VERSION ""

NS_ :

BS_:

BU_: OffBoardDiagnosticTool1 Modine_40TC0063
VAL_TABLE_ FE 255 "Not Used" 254 "Unavailable" ;
VAL_TABLE_ FEFF 65535 "Not Used" 65279 "Unavailable" ;
VAL_TABLE_ exv_state_machine 3 "Complete" 2 "In Process" 1 "Start Request" 0 "Idle" ;
VAL_TABLE_ Manual_off_16 65535 "Manual mode disabled" ;
VAL_TABLE_ Manual_off_8 255 "Manual mode disabled" ;
VAL_TABLE_ cond_pressure_override 1 "On - set to 1450 kPa-g" 0 "Off - Auto pressure SP" ;
VAL_TABLE_ Pressure_switch 3 "Invalid" 1 "Closed (OK)" 0 "Open (fault)" ;
VAL_TABLE_ Digital_in 3 "Invalid" 1 "High (24V)" 0 "Low (0V)" ;

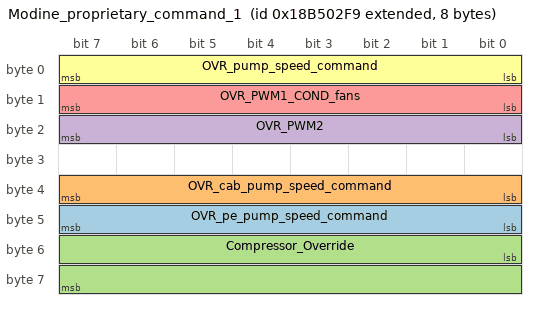
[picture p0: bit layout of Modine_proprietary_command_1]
BO_ 2561999609 Modine_proprietary_command_1: 8 OffBoardDiagnosticTool1
 SG_ OVR_pe_pump_speed_command : 40|8@1+ (0.5,0) [0|127.5] "%" Vector__XXX
 SG_ OVR_cab_pump_speed_command : 32|8@1+ (0.5,0) [0|127.5] "%" Vector__XXX
 SG_ Compressor_Override : 48|16@1+ (1,0) [0|65535] "" Vector__XXX
 SG_ OVR_PWM2 : 16|8@1+ (0.5,0) [0|127.5] "%"  Modine_40TC0063
 SG_ OVR_PWM1_COND_fans : 8|8@1+ (0.5,0) [0|127.5] "%"  Modine_40TC0063
 SG_ OVR_pump_speed_command : 0|8@1+ (0.5,0) [0|127.5] "%"  Modine_40TC0063

CM_ "V1.0 - Initial Release";
CM_ SG_ 2561999609 OVR_pe_pump_speed_command "Transmit 0xFF to disable";
CM_ SG_ 2561999609 OVR_cab_pump_speed_command "Transmit 0xFF to disable";
CM_ SG_ 2561999609 OVR_PWM1_COND_fans "3% - Fan off
20% - Fan reverse
40% - Minimum forward speed
90%+ - Maximum forward speed";
CM_ SG_ 2561999609 OVR_pump_speed_command "Transmit 0xFF to disable";
BA_DEF_ SG_  "J1939SLOT" STRING ;
BA_DEF_  "BaudRate" STRING ;
BA_DEF_  "DatabaseVersionDate" STRING ;
BA_DEF_  "DatabaseVersion" STRING ;
BA_DEF_ SG_  "SigType" ENUM  "Default","Range","RangeSigned","ASCII","Discrete","Control","ReferencePGN","DTC","StringDelimiter","StringLength","StringLengthControl","MessageCounter","MessageChecksum";
BA_DEF_ SG_  "GenSigEVName" STRING ;
BA_DEF_ SG_  "GenSigILSupport" ENUM  "No","Yes";
BA_DEF_ SG_  "GenSigSendType" ENUM  "Cyclic","OnWrite","OnWriteWithRepetition","OnChange","OnChangeWithRepetition","IfActive","IfActiveWithRepetition","NoSigSendType";
BA_DEF_ SG_  "GenSigStartValue" INT 0 2147483647;
BA_DEF_ BO_  "GenMsgILSupport" ENUM  "No","Yes";
BA_DEF_ BU_  "NmStationAddress" INT 0 255;
BA_DEF_ BO_  "GenMsgSendType" ENUM  "cyclic","NotUsed","IfActive","NotUsed","NotUsed","NotUsed","NotUsed","NotUsed","noMsgSendType";
BA_DEF_ BO_  "GenMsgRequestable" INT 0 1;
BA_DEF_ BO_  "GenMsgCycleTime" INT 0 3600000;
BA_DEF_  "DBName" STRING ;
BA_DEF_  "BusType" STRING ;
BA_DEF_  "ProtocolType" STRING ;
BA_DEF_ BO_  "VFrameFormat" ENUM  "StandardCAN","ExtendedCAN","reserved","J1939PG";
BA_DEF_DEF_  "J1939SLOT" "-";
BA_DEF_DEF_  "BaudRate" "500K";
BA_DEF_DEF_  "DatabaseVersionDate" "1-March-2022";
BA_DEF_DEF_  "DatabaseVersion" "";
BA_DEF_DEF_  "SigType" "Default";
BA_DEF_DEF_  "GenSigEVName" "Env@Nodename_@Signame";
BA_DEF_DEF_  "GenSigILSupport" "Yes";
BA_DEF_DEF_  "GenSigSendType" "NoSigSendType";
BA_DEF_DEF_  "GenSigStartValue" 0;
BA_DEF_DEF_  "GenMsgILSupport" "Yes";
BA_DEF_DEF_  "NmStationAddress" 254;
BA_DEF_DEF_  "GenMsgSendType" "noMsgSendType";
BA_DEF_DEF_  "GenMsgRequestable" 1;
BA_DEF_DEF_  "GenMsgCycleTime" 0;
BA_DEF_DEF_  "DBName" "";
BA_DEF_DEF_  "BusType" "CAN";
BA_DEF_DEF_  "ProtocolType" "J1939";
BA_DEF_DEF_  "VFrameFormat" "J1939PG";
BA_ "DatabaseVersionDate" "11-Dec-2025";
BA_ "DatabaseVersion" "1.14.0";
BA_ "BaudRate" "500k";
BA_ "DBName" "Modine_proprietary";
BA_ "NmStationAddress" BU_ OffBoardDiagnosticTool1 249;
BA_ "NmStationAddress" BU_ Modine_40TC0063 188;
BA_ "GenMsgCycleTime" BO_ 2561999609 100;
BA_ "GenSigStartValue" SG_ 2561999609 OVR_pe_pump_speed_command 255;
BA_ "GenSigStartValue" SG_ 2561999609 OVR_cab_pump_speed_command 255;
BA_ "GenSigStartValue" SG_ 2561999609 Compressor_Override 65535;
BA_ "GenSigStartValue" SG_ 2561999609 OVR_PWM2 255;
BA_ "GenSigStartValue" SG_ 2561999609 OVR_PWM1_COND_fans 255;
BA_ "GenSigStartValue" SG_ 2561999609 OVR_pump_speed_command 255;
VAL_ 2561999609 OVR_pe_pump_speed_command 255 "Manual mode disabled" ;
VAL_ 2561999609 OVR_cab_pump_speed_command 255 "Manual mode disabled" ;
VAL_ 2561999609 Compressor_Override 65535 "Not Used" 65279 "Unavailable" ;
VAL_ 2561999609 OVR_PWM2 255 "Manual mode disabled" ;
VAL_ 2561999609 OVR_PWM1_COND_fans 255 "Manual mode disabled" ;
VAL_ 2561999609 OVR_pump_speed_command 255 "Manual mode disabled" ;
